AUTOSAR XML (schema 4-2-2)
package /Components
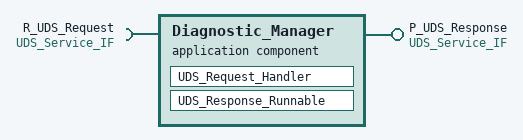
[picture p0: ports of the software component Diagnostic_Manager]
  application sw component type Diagnostic_Manager
    provide port P_UDS_Response: provided-interface=UDS_Service_IF
    require port R_UDS_Request: required-interface=UDS_Service_IF
    behavior Diagnostic_Manager_Behavior
      init event Diag_Init: start-on-event=UDS_Request_Handler
      operation invoked event UDS_Service_Invoked: start-on-event=UDS_Request_Handler, operation=P_UDS_Response.HandleRequest
      runnable UDS_Request_Handler: symbol=Runnable_UDS_Request_Handler
        data-receive-point-by-arguments:
          access Recv_UDS_Request_Var: accessed-variable=R_UDS_Request.UDS_Request
        data-send-points:
          access Send_UDS_Response_Var: accessed-variable=P_UDS_Response.UDS_Response
        sync call NV_Read_Write_Call: operation=R_UDS_Request.ReadWriteDTC, timeout=50
      runnable UDS_Response_Runnable: symbol=Runnable_UDS_Response_Runnable
        data-receive-point-by-arguments:
          access Recv_Internal_Response: accessed-variable=P_UDS_Response.UDS_Response
        data-send-points:
          access Send_UDS_Response_Var: accessed-variable=P_UDS_Response.UDS_Response
        sync call NV_Write_Call: operation=R_UDS_Request.WriteDTC, timeout=100
